# PRU_ICSSG0_PA_STAT_WRAP_PA_SLV_local register map
Vendor: Texas Instruments
Peripheral module from a debugger description file (folder am65x).
Registers are 32-bit, read-write, reset 0x0 unless marked. A register's access mark holds for its fields unless they carry their own. Offsets are as the file gives them; lines under a group give offsets from that group; [hi:lo] are bit positions; {n}, {i} and the like mark numbered series; 'fields as' and 'values as' point back to an identical list; <NAME> marks a mode.

## PRU_ICSSG0_PA_STAT_WRAP_PA_SLV
0x00 ICSSG_PA_STAT_REVID ro reset 0xEF50100 — Return to the . The Revision Register contains the ID and revision information.
  [31:0] REVID — Module ID and revision information.
0x04 ICSSG_PA_STAT_SRESET wo — Return to the . The Soft Reset Register is written in order to clear the contents of all statistics.
  [31:0] TRIGGER — Writing anything to this field causes the command FIFOs to be emptied, all statistics to be cleared and all bit masks to be reset to 1. The write to this register will be acknowledged (wready will be asserted) after the reset process is completed.
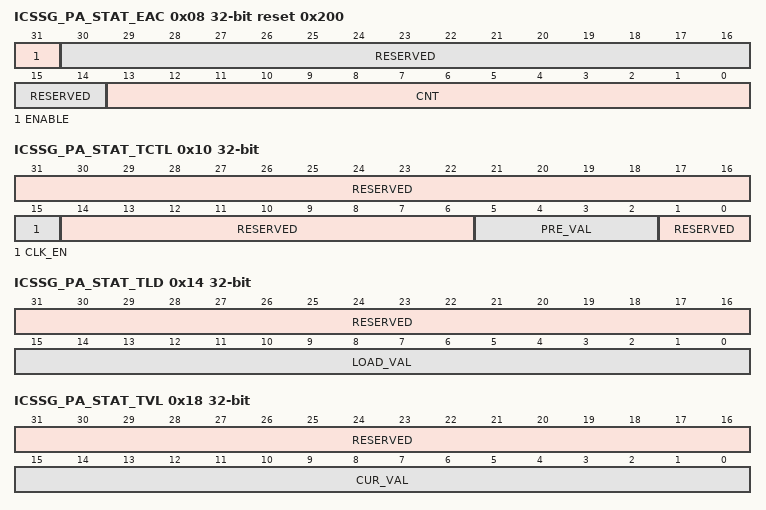
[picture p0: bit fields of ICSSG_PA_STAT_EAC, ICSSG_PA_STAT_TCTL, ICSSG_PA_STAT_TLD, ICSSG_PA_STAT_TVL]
0x08 ICSSG_PA_STAT_EAC reset 0x200 (reset mask 0x80003FFF) — Return to the . The register contains the enable for the engine and controls the allocation of 64-bit counters in the memory. It is possible to configure the engine to only have 32-bit counters by setting the 64-bit cnt field to zero.
  [31] ENABLE — Enables stat engine. If the module is not in enabled state, no stats increment is processed and both input and output streaming interfaces are disabled.
  [30:14] RESERVED — Always read as 0. Writes have no effect.
  [13:0] CNT — Defines the number of 64-bit counters in the memory (must be even number). If this number multiplied by 8-byte is less than 4KB (stats memory space), then the remaining space is allocated for 32-bit counters.
0x10 ICSSG_PA_STAT_TCTL (reset mask 0x803C) — Return to the . The Control Timer Register controls a 16-bit timer.
  [31:16] RESERVED — Always read as 0. Writes have no effect.
  [15] CLK_EN — 0 = Disable prescaler 1 = Enable prescaler
  [14:6] RESERVED — Always read as 0. Writes have no effect.
  [5:2] PRE_VAL — 0000 Divide by 2 0001 Divide by 4 0010 Divide by 8 0011 Divide by 16 0100 Divide by 32 0101 Divide by 64 0110 Divide by 128 0111 Divide by 256 1000 Divide by 512 1001 Divide by 1024 1010 Divide by 2048 1011 Divide by 1024 1100 Divide by 8192 1101 Disable timer 1110 Disable timer 1111 Disable timer
  [1:0] RESERVED — Always read as 0. Writes have no effect.
0x14 ICSSG_PA_STAT_TLD (reset mask 0xFFFF) — Return to the . The Load Timer Register contains the starting count down value for the 16-bit timer. This register should be written with some value before the timer is started by write on the timer control register.
  [31:16] RESERVED — Always read as 0. Writes have no effect.
  [15:0] LOAD_VAL — 16-bit timer value.
0x18 ICSSG_PA_STAT_TVL ro (reset mask 0xFFFF) — Return to the . The Timer Value Register contains the current value of the timer.
  [31:16] RESERVED — Always read as 0. Writes have no effect.
  [15:0] CUR_VAL — Current value of the 16-bit timer.
